# STM32U083xx register map
File version: 1.0
Registers are 32-bit, read-write, reset 0x0 unless marked. A register's access mark holds for its fields unless they carry their own. Offsets are from the block's base; [hi:lo] are bit positions; {n}, {i} and the like mark numbered series.

## RNG
Base 0x40025000
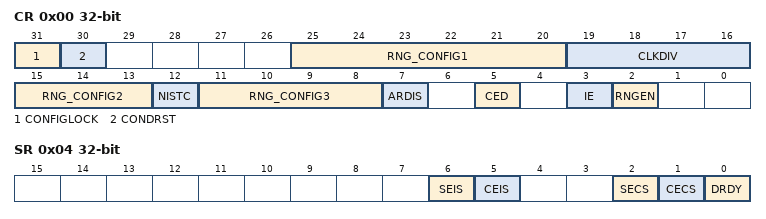
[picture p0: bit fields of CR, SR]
0x00 CR — RNG control register
  [31] CONFIGLOCK
  [30] CONDRST
  [25:20] RNG_CONFIG1
  [19:16] CLKDIV
    0=BY_1 (No clock division); 1=BY_2 (2 RNG clock cycles per internal RNG clock); 2=BY_4 (4 RNG clock cycles per internal RNG clock); 3=BY_8 (8 RNG clock cycles per internal RNG clock); 4=BY_16 (16 RNG clock cycles per internal RNG clock); 5=BY_32 (32 RNG clock cycles per internal RNG clock); 6=BY_64 (64 RNG clock cycles per internal RNG clock); 7=BY_128 (128 RNG clock cycles per internal RNG clock); 8=BY_256 (256 RNG clock cycles per internal RNG clock); 9=BY_512 (512 RNG clock cycles per internal RNG clock); 10=BY_1024 (1024 RNG clock cycles per internal RNG clock); 11=BY_2048 (2048 RNG clock cycles per internal RNG clock); 12=BY_4096 (4096 RNG clock cycles per internal RNG clock); 13=BY_8192 (8192 RNG clock cycles per internal RNG clock); 14=BY_16384 (16384 RNG clock cycles per internal RNG clock); 15=BY_32768 (32768 RNG clock cycles per internal RNG clock)
  [15:13] RNG_CONFIG2
  [12] NISTC
  [11:8] RNG_CONFIG3
  [7] ARDIS
  [5] CED
  [3] IE
  [2] RNGEN
0x04 SR — RNG status register
  [6] SEIS, [5] CEIS, [2] SECS, [1] CECS, [0] DRDY
0x08 DR — RNG data register
0x10 HTCR — RNG health test configuration register
  [31:0] HTCFG

## AES — AES hardware accelerator
Base 0x40026000
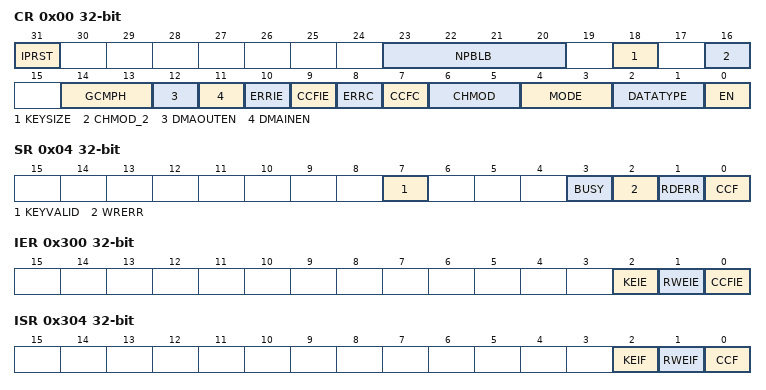
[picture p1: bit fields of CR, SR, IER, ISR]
0x00 CR — AES control register
  [31] IPRST — AES IP software reset
  [23:20] NPBLB — Number of padding bytes in payload last block
  [18] KEYSIZE — Key size selection
  [16] CHMOD_2 — AES Chaining Mode
  [14:13] GCMPH — GCM Phase
  [12] DMAOUTEN — Enable data output phase DMA management
  [11] DMAINEN — Enable data input phase DMA management
  [10] ERRIE — Error Interrupt Enable
  [9] CCFIE — Computation Complete Flag Interrupt Enable
  [8] ERRC — Error Clear
  [7] CCFC — Computation Complete Flag Clear
  [6:5] CHMOD — AES Chaining Mode
  [4:3] MODE — AES Mode Of Operation
  [2:1] DATATYPE — Data type selection
  [0] EN — AES Enable
0x04 SR — AES status register
  [7] KEYVALID — Key Valid Flag
  [3] BUSY — Busy Flag
  [2] WRERR — Write Error Flag
  [1] RDERR — Read Error Flag
  [0] CCF — Computation Complete Flag
0x08 DINR — AES data input register
  [31:0] DINR — AES Data Input Register
0x0C DOUTR — AES data output register
  [31:0] DOUTR — AES Data Output Register
{0x10+4i} KEYR{i} (i=0..3) — AES key register {i}
  [31:0] KEYR{i} — AES Key Register {i}
{0x20+4i} IVR{i} (i=0..3) — AES initialization vector register {i}
  [31:0] IVR{i} — AES Initialization Vector Register {i}
{0x20+4i} KEYR{i} (i=4..7) — AES key register {i}
  [31:0] KEYR{i} — AES Key Register {i}
{0x40+4i} SUSPR{i} (i=0..7) — AES Suspend register {i}
  [31:0] SUSPR{i} — AES Suspend registers {i}
0x300 IER — AES Interrupt Enable Register
  [2] KEIE — Key error interrupt enable
  [1] RWEIE — Read or write error Interrupt Enable
  [0] CCFIE — Computation complete flag interrupt enable
0x304 ISR — AES Interrupt Status Register
  [2] KEIF — Key error interrupt flag
  [1] RWEIF — Read or write error Interrupt flag
  [0] CCF — Computation complete flag
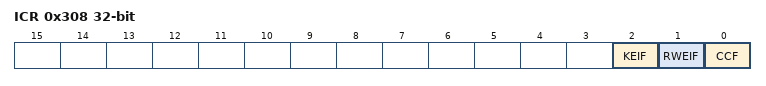
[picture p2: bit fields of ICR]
0x308 ICR — AES Interrupt Clear Register
  [2] KEIF — Key error interrupt flag clear
  [1] RWEIF — Read or write error Interrupt flag clear
  [0] CCF — Computation complete flag clear

## GPIOA — General Purpose I/O
Base 0x50000000
Same registers: GPIOB 0x50000400, GPIOC 0x50000800, GPIOD 0x50000C00, GPIOE 0x50001000, GPIOF 0x50001400
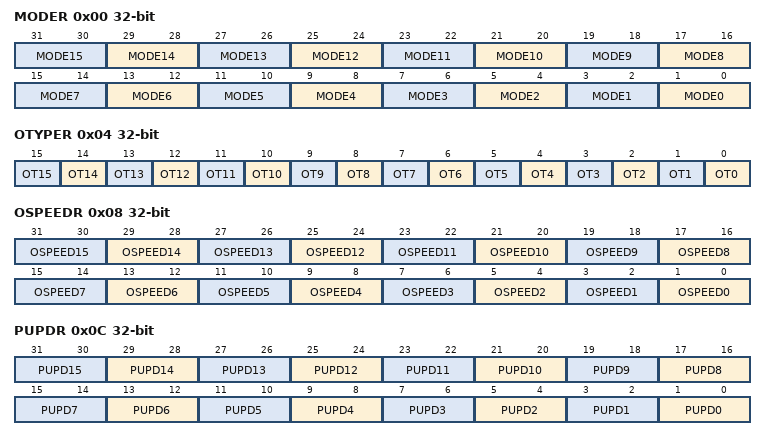
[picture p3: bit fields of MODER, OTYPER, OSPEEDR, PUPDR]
0x00 MODER — GPIO port mode register
  [2n+1:2n] MODE{n} (n=0..15)
0x04 OTYPER — GPIO port output type register
  [n] OT{n} (n=0..15)
0x08 OSPEEDR — GPIO port output speed register
  [2n+1:2n] OSPEED{n} (n=0..15)
0x0C PUPDR — GPIO port pull-up/pull-down register
  [2n+1:2n] PUPD{n} (n=0..15)
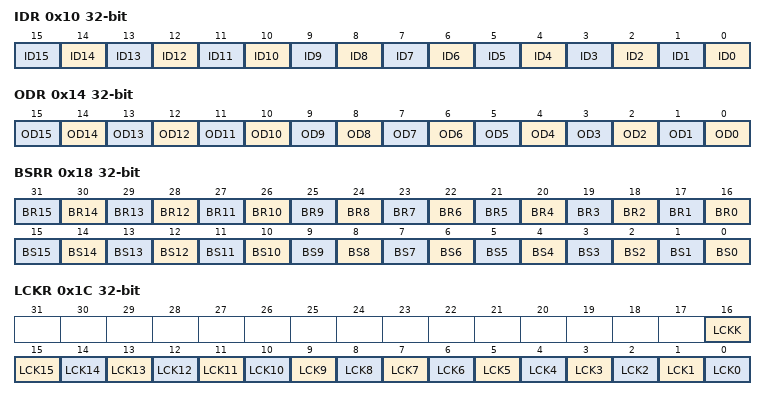
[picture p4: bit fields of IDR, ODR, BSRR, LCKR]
0x10 IDR — GPIO port input data register
  [n] ID{n} (n=0..15)
0x14 ODR — GPIO port output data register
  [n] OD{n} (n=0..15)
0x18 BSRR — GPIO port bit set/reset register
  [n+16] BR{n} (n=0..15), [n] BS{n} (n=0..15)
0x1C LCKR — GPIO port configuration lock register
  [16] LCKK, [n] LCK{n} (n=0..15)
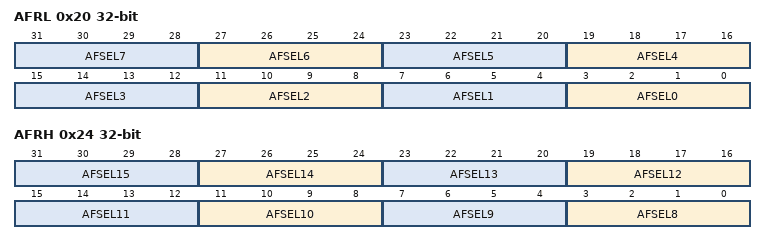
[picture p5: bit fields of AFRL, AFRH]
0x20 AFRL — GPIO alternate function registers
  [4n+3:4n] AFSEL{n} (n=0..7)
0x24 AFRH — GPIO alternate function registers
  [4n-29:4n-32] AFSEL{n} (n=8..15)
0x28 BRR — GPIO Bit Reset register
